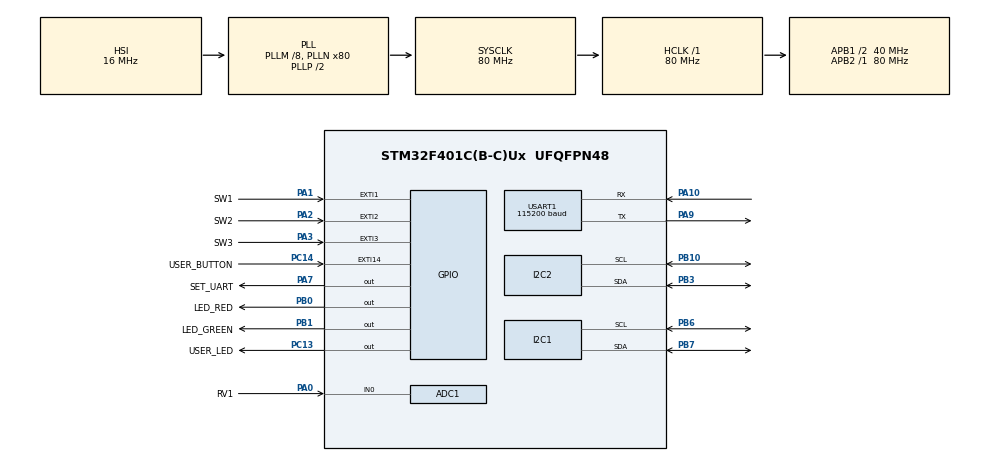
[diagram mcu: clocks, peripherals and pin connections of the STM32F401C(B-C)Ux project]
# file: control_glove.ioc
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ADC1.Channel-0\#ChannelRegularConversion=ADC_CHANNEL_0
ADC1.ContinuousConvMode=ENABLE
ADC1.NbrOfConversion=1
ADC1.NbrOfConversionFlag=1
ADC1.Rank-0\#ChannelRegularConversion=1
ADC1.SamplingTime-0\#ChannelRegularConversion=ADC_SAMPLETIME_3CYCLES
ADC1.ScanConvMode=ENABLE
ADC1.master=1
Dma.I2C1_RX.1.Direction=DMA_PERIPH_TO_MEMORY
Dma.I2C1_RX.1.FIFOMode=DMA_FIFOMODE_DISABLE
Dma.I2C1_RX.1.Instance=DMA1_Stream0
Dma.I2C1_RX.1.MemDataAlignment=DMA_MDATAALIGN_BYTE
Dma.I2C1_RX.1.MemInc=DMA_MINC_ENABLE
Dma.I2C1_RX.1.Mode=DMA_NORMAL
Dma.I2C1_RX.1.PeriphDataAlignment=DMA_PDATAALIGN_BYTE
Dma.I2C1_RX.1.PeriphInc=DMA_PINC_DISABLE
Dma.I2C1_RX.1.Priority=DMA_PRIORITY_LOW
Dma.I2C2_RX.0.Direction=DMA_PERIPH_TO_MEMORY
Dma.I2C2_RX.0.FIFOMode=DMA_FIFOMODE_DISABLE
Dma.I2C2_RX.0.Instance=DMA1_Stream2
Dma.I2C2_RX.0.MemDataAlignment=DMA_MDATAALIGN_BYTE
Dma.I2C2_RX.0.MemInc=DMA_MINC_ENABLE
Dma.I2C2_RX.0.Mode=DMA_NORMAL
Dma.I2C2_RX.0.PeriphDataAlignment=DMA_PDATAALIGN_BYTE
Dma.I2C2_RX.0.PeriphInc=DMA_PINC_DISABLE
Dma.I2C2_RX.0.Priority=DMA_PRIORITY_LOW
Dma.Request0=I2C2_RX
Dma.Request1=I2C1_RX
Mcu.Family=STM32F4
Mcu.Name=STM32F401C(B-C)Ux
Mcu.Package=UFQFPN48
NVIC.DMA1_Stream0_IRQn=true\:0\:0\:false\:false\:true\:false\:true
NVIC.DMA1_Stream2_IRQn=true\:0\:0\:false\:false\:true\:false\:true
NVIC.EXTI15_10_IRQn=true\:1\:0\:true\:false\:true\:true\:true
NVIC.EXTI1_IRQn=true\:0\:0\:false\:false\:true\:true\:true
NVIC.EXTI2_IRQn=true\:0\:0\:false\:false\:true\:true\:true
NVIC.EXTI3_IRQn=true\:0\:0\:false\:false\:true\:true\:true
NVIC.I2C1_EV_IRQn=true\:0\:0\:false\:false\:true\:true\:true
NVIC.I2C2_EV_IRQn=true\:0\:0\:false\:false\:true\:true\:true
NVIC.PriorityGroup=NVIC_PRIORITYGROUP_4
NVIC.TIM1_TRG_COM_TIM11_IRQn=true\:1\:0\:true\:false\:true\:true\:true
NVIC.USART1_IRQn=true\:1\:0\:true\:false\:true\:true\:true
PA0-WKUP.GPIO_Label=RV1
PA0-WKUP.Signal=ADCx_IN0
PA1.GPIO_Label=SW1
PA1.GPIO_ModeDefaultEXTI=GPIO_MODE_IT_FALLING
PA1.Signal=GPXTI1
PA10.Mode=Asynchronous
PA10.Signal=USART1_RX
PA13.Mode=Serial_Wire
PA13.Signal=SYS_JTMS-SWDIO
PA14.Mode=Serial_Wire
PA14.Signal=SYS_JTCK-SWCLK
PA2.GPIO_Label=SW2
PA2.GPIO_ModeDefaultEXTI=GPIO_MODE_IT_FALLING
PA2.Signal=GPXTI2
PA3.GPIO_Label=SW3
PA3.GPIO_ModeDefaultEXTI=GPIO_MODE_IT_FALLING
PA3.GPIO_PuPd=GPIO_NOPULL
PA3.Signal=GPXTI3
PA7.GPIO_Label=SET_UART
PA7.GPIO_ModeDefaultOutputPP=GPIO_MODE_OUTPUT_PP
PA7.GPIO_PuPd=GPIO_NOPULL
PA7.PinState=GPIO_PIN_SET
PA7.Signal=GPIO_Output
PA9.Mode=Asynchronous
PA9.Signal=USART1_TX
PB0.GPIO_Label=LED_RED
PB0.GPIO_PuPd=GPIO_NOPULL
PB0.Signal=GPIO_Output
PB1.GPIO_Label=LED_GREEN
PB1.GPIO_PuPd=GPIO_NOPULL
PB1.Signal=GPIO_Output
PB10.Mode=I2C
PB10.Signal=I2C2_SCL
PB3.Mode=I2C
PB3.Signal=I2C2_SDA
PB6.Mode=I2C
PB6.Signal=I2C1_SCL
PB7.Mode=I2C
PB7.Signal=I2C1_SDA
PC13-ANTI_TAMP.GPIO_Label=USER_LED
PC13-ANTI_TAMP.Signal=GPIO_Output
PC14-OSC32_IN.GPIO_Label=USER_BUTTON
PC14-OSC32_IN.GPIO_ModeDefaultEXTI=GPIO_MODE_IT_FALLING
PC14-OSC32_IN.GPIO_PuPd=GPIO_PULLUP
PC14-OSC32_IN.Signal=GPXTI14
ProjectManager.HeapSize=0x200
ProjectManager.StackSize=0x400
ProjectManager.TargetToolchain=STM32CubeIDE
RCC.48MHZClocksFreq_Value=40000000
RCC.AHBFreq_Value=80000000
RCC.APB1CLKDivider=RCC_HCLK_DIV2
RCC.APB1Freq_Value=40000000
RCC.APB1TimFreq_Value=80000000
RCC.APB2Freq_Value=80000000
RCC.APB2TimFreq_Value=80000000
RCC.CortexFreq_Value=80000000
RCC.HCLKFreq_Value=80000000
RCC.HSE_VALUE=25000000
RCC.HSI_VALUE=16000000
RCC.LSE_VALUE=32768
RCC.PLLM=8
RCC.PLLN=80
RCC.SYSCLKFreq_VALUE=80000000
RCC.SYSCLKSource=RCC_SYSCLKSOURCE_PLLCLK
RCC.VCOOutputFreq_Value=160000000
SH.ADCx_IN0.0=ADC1_IN0,IN0
TIM11.Channel=TIM_CHANNEL_1
USART1.BaudRate=115200
USART1.VirtualMode=VM_ASYNC
VP_TIM11_VS_ClockSourceINT.Mode=Enable_Timer
VP_TIM11_VS_no_output1.Mode=Output Compare1 No Output
board=custom

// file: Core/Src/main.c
/* USER CODE BEGIN Header */
/**
  ******************************************************************************
  * @file           : main.c
  * @brief          : Main program body
  ******************************************************************************
  * @attention
  *
  * <h2><center>&copy; Copyright (c) 2023 STMicroelectronics.
  * All rights reserved.</center></h2>
  *
  * This software component is licensed by ST under BSD 3-Clause license,
  * the "License"; You may not use this file except in compliance with the
  * License. You may obtain a copy of the License at:
  *                        opensource.org/licenses/BSD-3-Clause
  *
  ******************************************************************************
  */
/* USER CODE END Header */
#include "main.h"
#include "system_manager.h"

ADC_HandleTypeDef hadc1;

I2C_HandleTypeDef hi2c1;
I2C_HandleTypeDef hi2c2;
DMA_HandleTypeDef hdma_i2c1_rx;
DMA_HandleTypeDef hdma_i2c2_rx;

TIM_HandleTypeDef htim11;

UART_HandleTypeDef huart1;

void SystemClock_Config(void);
static void MX_GPIO_Init(void);
static void MX_DMA_Init(void);
static void MX_I2C1_Init(void);
static void MX_I2C2_Init(void);
static void MX_USART1_UART_Init(void);
static void MX_TIM11_Init(void);
static void MX_ADC1_Init(void);
/* USER CODE BEGIN PFP */
#ifdef __GNUC__
  #define PUTCHAR_PROTOTYPE int __io_putchar(int ch)
#else
  #define PUTCHAR_PROTOTYPE int fputc(int ch, FILE *f)
#endif /* __GNUC__ */
PUTCHAR_PROTOTYPE
{
    HAL_UART_Transmit(&huart1, (uint8_t *)&ch, 1, 100);
    return ch;
}
/* USER CODE END PFP */

int main(void)
{

  /* MCU Configuration--------------------------------------------------------*/

  /* Reset of all peripherals, Initializes the Flash interface and the Systick. */
  HAL_Init();

  /* Configure the system clock */
  SystemClock_Config();

  /* Initialize all configured peripherals */
  MX_GPIO_Init();
  MX_DMA_Init();
  MX_I2C1_Init();
  MX_I2C2_Init();
  MX_USART1_UART_Init();
  MX_TIM11_Init();
  MX_ADC1_Init();
  /* USER CODE BEGIN 2 */
  system_manager_init();
  // bsp_mpu6050_calib();
  /* USER CODE END 2 */

  /* Infinite loop */
  while (1)
  {
	system_manager_task();
  }
}

void SystemClock_Config(void)
{
  RCC_OscInitTypeDef RCC_OscInitStruct = {0};
  RCC_ClkInitTypeDef RCC_ClkInitStruct = {0};

  /** Configure the main internal regulator output voltage
  */
  __HAL_RCC_PWR_CLK_ENABLE();
  __HAL_PWR_VOLTAGESCALING_CONFIG(PWR_REGULATOR_VOLTAGE_SCALE2);
  /** Initializes the RCC Oscillators according to the specified parameters
  * in the RCC_OscInitTypeDef structure.
  */
  RCC_OscInitStruct.OscillatorType = RCC_OSCILLATORTYPE_HSI;
  RCC_OscInitStruct.HSIState = RCC_HSI_ON;
  RCC_OscInitStruct.HSICalibrationValue = RCC_HSICALIBRATION_DEFAULT;
  RCC_OscInitStruct.PLL.PLLState = RCC_PLL_ON;
  RCC_OscInitStruct.PLL.PLLSource = RCC_PLLSOURCE_HSI;
  RCC_OscInitStruct.PLL.PLLM = 8;
  RCC_OscInitStruct.PLL.PLLN = 80;
  RCC_OscInitStruct.PLL.PLLP = RCC_PLLP_DIV2;
  RCC_OscInitStruct.PLL.PLLQ = 4;
  if (HAL_RCC_OscConfig(&RCC_OscInitStruct) != HAL_OK)
  {
    Error_Handler();
  }
  /** Initializes the CPU, AHB and APB buses clocks
  */
  RCC_ClkInitStruct.ClockType = RCC_CLOCKTYPE_HCLK|RCC_CLOCKTYPE_SYSCLK
                              |RCC_CLOCKTYPE_PCLK1|RCC_CLOCKTYPE_PCLK2;
  RCC_ClkInitStruct.SYSCLKSource = RCC_SYSCLKSOURCE_PLLCLK;
  RCC_ClkInitStruct.AHBCLKDivider = RCC_SYSCLK_DIV1;
  RCC_ClkInitStruct.APB1CLKDivider = RCC_HCLK_DIV2;
  RCC_ClkInitStruct.APB2CLKDivider = RCC_HCLK_DIV1;

  if (HAL_RCC_ClockConfig(&RCC_ClkInitStruct, FLASH_LATENCY_2) != HAL_OK)
  {
    Error_Handler();
  }
}

static void MX_ADC1_Init(void)
{

  ADC_ChannelConfTypeDef sConfig = {0};

  /** Configure the global features of the ADC (Clock, Resolution, Data Alignment and number of conversion)
  */
  hadc1.Instance = ADC1;
  hadc1.Init.ClockPrescaler = ADC_CLOCK_SYNC_PCLK_DIV4;
  hadc1.Init.Resolution = ADC_RESOLUTION_12B;
  hadc1.Init.ScanConvMode = ENABLE;
  hadc1.Init.ContinuousConvMode = ENABLE;
  hadc1.Init.DiscontinuousConvMode = DISABLE;
  hadc1.Init.ExternalTrigConvEdge = ADC_EXTERNALTRIGCONVEDGE_NONE;
  hadc1.Init.ExternalTrigConv = ADC_SOFTWARE_START;
  hadc1.Init.DataAlign = ADC_DATAALIGN_RIGHT;
  hadc1.Init.NbrOfConversion = 1;
  hadc1.Init.DMAContinuousRequests = DISABLE;
  hadc1.Init.EOCSelection = ADC_EOC_SINGLE_CONV;
  if (HAL_ADC_Init(&hadc1) != HAL_OK)
  {
    Error_Handler();
  }
  /** Configure for the selected ADC regular channel its corresponding rank in the sequencer and its sample time.
  */
  sConfig.Channel = ADC_CHANNEL_0;
  sConfig.Rank = 1;
  sConfig.SamplingTime = ADC_SAMPLETIME_3CYCLES;
  if (HAL_ADC_ConfigChannel(&hadc1, &sConfig) != HAL_OK)
  {
    Error_Handler();
  }

}

static void MX_I2C1_Init(void)
{

  hi2c1.Instance = I2C1;
  hi2c1.Init.ClockSpeed = 100000;
  hi2c1.Init.DutyCycle = I2C_DUTYCYCLE_2;
  hi2c1.Init.OwnAddress1 = 0;
  hi2c1.Init.AddressingMode = I2C_ADDRESSINGMODE_7BIT;
  hi2c1.Init.DualAddressMode = I2C_DUALADDRESS_DISABLE;
  hi2c1.Init.OwnAddress2 = 0;
  hi2c1.Init.GeneralCallMode = I2C_GENERALCALL_DISABLE;
  hi2c1.Init.NoStretchMode = I2C_NOSTRETCH_DISABLE;
  if (HAL_I2C_Init(&hi2c1) != HAL_OK)
  {
    Error_Handler();
  }

}

static void MX_I2C2_Init(void)
{

  hi2c2.Instance = I2C2;
  hi2c2.Init.ClockSpeed = 100000;
  hi2c2.Init.DutyCycle = I2C_DUTYCYCLE_2;
  hi2c2.Init.OwnAddress1 = 0;
  hi2c2.Init.AddressingMode = I2C_ADDRESSINGMODE_7BIT;
  hi2c2.Init.DualAddressMode = I2C_DUALADDRESS_DISABLE;
  hi2c2.Init.OwnAddress2 = 0;
  hi2c2.Init.GeneralCallMode = I2C_GENERALCALL_DISABLE;
  hi2c2.Init.NoStretchMode = I2C_NOSTRETCH_DISABLE;
  if (HAL_I2C_Init(&hi2c2) != HAL_OK)
  {
    Error_Handler();
  }

}

static void MX_TIM11_Init(void)
{

  TIM_OC_InitTypeDef sConfigOC = {0};

  htim11.Instance = TIM11;
  htim11.Init.Prescaler = 0;
  htim11.Init.CounterMode = TIM_COUNTERMODE_UP;
  htim11.Init.Period = 65535;
  htim11.Init.ClockDivision = TIM_CLOCKDIVISION_DIV1;
  htim11.Init.AutoReloadPreload = TIM_AUTORELOAD_PRELOAD_DISABLE;
  if (HAL_TIM_Base_Init(&htim11) != HAL_OK)
  {
    Error_Handler();
  }
  if (HAL_TIM_OC_Init(&htim11) != HAL_OK)
  {
    Error_Handler();
  }
  sConfigOC.OCMode = TIM_OCMODE_TIMING;
  sConfigOC.Pulse = 0;
  sConfigOC.OCPolarity = TIM_OCPOLARITY_HIGH;
  sConfigOC.OCFastMode = TIM_OCFAST_DISABLE;
  if (HAL_TIM_OC_ConfigChannel(&htim11, &sConfigOC, TIM_CHANNEL_1) != HAL_OK)
  {
    Error_Handler();
  }

}

static void MX_USART1_UART_Init(void)
{

  huart1.Instance = USART1;
  huart1.Init.BaudRate = 115200;
  huart1.Init.WordLength = UART_WORDLENGTH_8B;
  huart1.Init.StopBits = UART_STOPBITS_1;
  huart1.Init.Parity = UART_PARITY_NONE;
  huart1.Init.Mode = UART_MODE_TX_RX;
  huart1.Init.HwFlowCtl = UART_HWCONTROL_NONE;
  huart1.Init.OverSampling = UART_OVERSAMPLING_16;
  if (HAL_UART_Init(&huart1) != HAL_OK)
  {
    Error_Handler();
  }

}

static void MX_DMA_Init(void)
{

  /* DMA controller clock enable */
  __HAL_RCC_DMA1_CLK_ENABLE();

  /* DMA interrupt init */
  /* DMA1_Stream0_IRQn interrupt configuration */
  HAL_NVIC_SetPriority(DMA1_Stream0_IRQn, 0, 0);
  HAL_NVIC_EnableIRQ(DMA1_Stream0_IRQn);
  /* DMA1_Stream2_IRQn interrupt configuration */
  HAL_NVIC_SetPriority(DMA1_Stream2_IRQn, 0, 0);
  HAL_NVIC_EnableIRQ(DMA1_Stream2_IRQn);

}

static void MX_GPIO_Init(void)
{
  GPIO_InitTypeDef GPIO_InitStruct = {0};

  /* GPIO Ports Clock Enable */
  __HAL_RCC_GPIOC_CLK_ENABLE();
  __HAL_RCC_GPIOA_CLK_ENABLE();
  __HAL_RCC_GPIOB_CLK_ENABLE();

  /*Configure GPIO pin Output Level */
  HAL_GPIO_WritePin(USER_LED_GPIO_Port, USER_LED_Pin, GPIO_PIN_RESET);

  /*Configure GPIO pin Output Level */
  HAL_GPIO_WritePin(SET_UART_GPIO_Port, SET_UART_Pin, GPIO_PIN_SET);

  /*Configure GPIO pin Output Level */
  HAL_GPIO_WritePin(GPIOB, LED_RED_Pin|LED_GREEN_Pin, GPIO_PIN_RESET);

  /*Configure GPIO pin : USER_LED_Pin */
  GPIO_InitStruct.Pin = USER_LED_Pin;
  GPIO_InitStruct.Mode = GPIO_MODE_OUTPUT_PP;
  GPIO_InitStruct.Pull = GPIO_NOPULL;
  GPIO_InitStruct.Speed = GPIO_SPEED_FREQ_LOW;
  HAL_GPIO_Init(USER_LED_GPIO_Port, &GPIO_InitStruct);

  /*Configure GPIO pin : USER_BUTTON_Pin */
  GPIO_InitStruct.Pin = USER_BUTTON_Pin;
  GPIO_InitStruct.Mode = GPIO_MODE_IT_FALLING;
  GPIO_InitStruct.Pull = GPIO_PULLUP;
  HAL_GPIO_Init(USER_BUTTON_GPIO_Port, &GPIO_InitStruct);

  /*Configure GPIO pins : SW1_Pin SW2_Pin SW3_Pin */
  GPIO_InitStruct.Pin = SW1_Pin|SW2_Pin|SW3_Pin;
  GPIO_InitStruct.Mode = GPIO_MODE_IT_FALLING;
  GPIO_InitStruct.Pull = GPIO_NOPULL;
  HAL_GPIO_Init(GPIOA, &GPIO_InitStruct);

  /*Configure GPIO pin : SET_UART_Pin */
  GPIO_InitStruct.Pin = SET_UART_Pin;
  GPIO_InitStruct.Mode = GPIO_MODE_OUTPUT_PP;
  GPIO_InitStruct.Pull = GPIO_NOPULL;
  GPIO_InitStruct.Speed = GPIO_SPEED_FREQ_LOW;
  HAL_GPIO_Init(SET_UART_GPIO_Port, &GPIO_InitStruct);

  /*Configure GPIO pins : LED_RED_Pin LED_GREEN_Pin */
  GPIO_InitStruct.Pin = LED_RED_Pin|LED_GREEN_Pin;
  GPIO_InitStruct.Mode = GPIO_MODE_OUTPUT_PP;
  GPIO_InitStruct.Pull = GPIO_NOPULL;
  GPIO_InitStruct.Speed = GPIO_SPEED_FREQ_LOW;
  HAL_GPIO_Init(GPIOB, &GPIO_InitStruct);

  /* EXTI interrupt init*/
  HAL_NVIC_SetPriority(EXTI1_IRQn, 0, 0);
  HAL_NVIC_EnableIRQ(EXTI1_IRQn);

  HAL_NVIC_SetPriority(EXTI2_IRQn, 0, 0);
  HAL_NVIC_EnableIRQ(EXTI2_IRQn);

  HAL_NVIC_SetPriority(EXTI3_IRQn, 0, 0);
  HAL_NVIC_EnableIRQ(EXTI3_IRQn);

  HAL_NVIC_SetPriority(EXTI15_10_IRQn, 1, 0);
  HAL_NVIC_EnableIRQ(EXTI15_10_IRQn);

}

void Error_Handler(void)
{
  __disable_irq();
  while (1)
  {
  }
}

/************************ (C) COPYRIGHT STMicroelectronics *****END OF FILE****/
